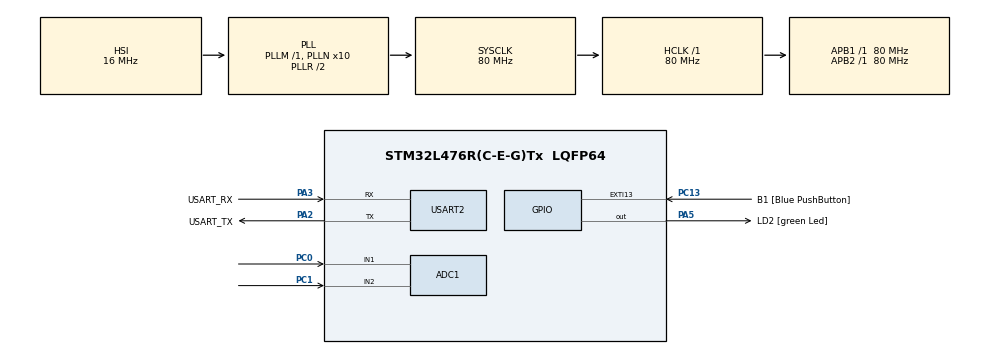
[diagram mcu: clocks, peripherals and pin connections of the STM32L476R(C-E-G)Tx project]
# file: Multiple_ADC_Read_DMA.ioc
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Mcu.Family=STM32L4
PA2.GPIO_PuPd=GPIO_NOPULL
RCC.CortexFreq_Value=80000000
ADC1.ContinuousConvMode=ENABLE
PH0-OSC_IN\ (PH0).Signal=RCC_OSC_IN
SH.ADCx_IN2.0=ADC1_IN2,IN2-Single-Ended
PA3.GPIO_PuPd=GPIO_NOPULL
PA2.GPIO_Speed=GPIO_SPEED_FREQ_VERY_HIGH
PC15-OSC32_OUT\ (PC15).Mode=LSE-External-Oscillator
PC13.GPIO_Label=B1 [Blue PushButton]
PA3.GPIO_Speed=GPIO_SPEED_FREQ_VERY_HIGH
RCC.SYSCLKSource=RCC_SYSCLKSOURCE_PLLCLK
ProjectManager.StackSize=0x400
PB3\ (JTDO-TRACESWO).Signal=SYS_JTDO-SWO
PC14-OSC32_IN\ (PC14).Mode=LSE-External-Oscillator
PA14\ (JTCK-SWCLK).Signal=SYS_JTCK-SWCLK
RCC.HCLKFreq_Value=80000000
RCC.APB2TimFreq_Value=80000000
Dma.ADC1.0.Direction=DMA_PERIPH_TO_MEMORY
Dma.ADC1.0.MemDataAlignment=DMA_MDATAALIGN_WORD
RCC.AHBFreq_Value=80000000
RCC.PREFETCH_ENABLE=1
ADC1.Channel-0\#ChannelRegularConversion=ADC_CHANNEL_1
RCC.HSE_VALUE=8000000
USART2.VirtualMode-Asynchronous=VM_ASYNC
Dma.ADC1.0.PeriphInc=DMA_PINC_DISABLE
PA5.GPIO_PuPd=GPIO_NOPULL
PC13.GPIO_PuPd=GPIO_NOPULL
ADC1.SamplingTime-0\#ChannelRegularConversion=ADC_SAMPLETIME_92CYCLES_5
Mcu.Package=LQFP64
PA2.GPIO_Label=USART_TX
ADC1.OffsetNumber-1\#ChannelRegularConversion=ADC_OFFSET_NONE
SH.ADCx_IN1.0=ADC1_IN1,IN1-Single-Ended
RCC.APB1TimFreq_Value=80000000
PA13\ (JTMS-SWDIO).Signal=SYS_JTMS-SWDIO
Dma.Request0=ADC1
PA3.Signal=USART2_RX
PA2.GPIO_Mode=GPIO_MODE_AF_PP
RCC.MSI_VALUE=4000000
RCC.PLLSourceVirtual=RCC_PLLSOURCE_HSI
PA14\ (JTCK-SWCLK).Mode=Serial_Wire
Dma.ADC1.0.Instance=DMA1_Channel1
ADC1.Rank-0\#ChannelRegularConversion=1
ADC1.OffsetNumber-0\#ChannelRegularConversion=ADC_OFFSET_NONE
PC13.Signal=GPXTI13
PC15-OSC32_OUT\ (PC15).Signal=RCC_OSC32_OUT
PA14\ (JTCK-SWCLK).GPIO_Label=TCK
PB3\ (JTDO-TRACESWO).GPIO_Label=SWO
PC0.Signal=ADCx_IN1
PH1-OSC_OUT\ (PH1).Signal=RCC_OSC_OUT
PA3.Mode=Asynchronous
Dma.ADC1.0.PeriphDataAlignment=DMA_PDATAALIGN_WORD
ProjectManager.TargetToolchain=MDK-ARM V5.27
Dma.ADC1.0.Mode=DMA_NORMAL
PA3.GPIO_Mode=GPIO_MODE_AF_PP
Dma.ADC1.0.Priority=DMA_PRIORITY_MEDIUM
ADC1.Channel-1\#ChannelRegularConversion=ADC_CHANNEL_2
RCC.USBFreq_Value=64000000
PA5.Signal=GPIO_Output
board=NUCLEO-L476RG
RCC.VCOOutputFreq_Value=160000000
RCC.APB2Freq_Value=80000000
PA5.GPIO_ModeDefaultOutputPP=GPIO_MODE_OUTPUT_PP
PA13\ (JTMS-SWDIO).GPIO_Label=TMS
RCC.ADCFreq_Value=64000000
ADC1.NbrOfConversion=2
Mcu.Name=STM32L476R(C-E-G)Tx
PA2.Signal=USART2_TX
PA13\ (JTMS-SWDIO).Mode=Serial_Wire
ADC1.SamplingTime-1\#ChannelRegularConversion=ADC_SAMPLETIME_92CYCLES_5
RCC.SYSCLKFreq_VALUE=80000000
ADC1.master=1
PA5.GPIO_Label=LD2 [green Led]
PC13.GPIO_ModeDefaultEXTI=GPIO_MODE_IT_FALLING
PC14-OSC32_IN\ (PC14).Signal=RCC_OSC32_IN
ADC1.Rank-1\#ChannelRegularConversion=2
Dma.ADC1.0.MemInc=DMA_MINC_ENABLE
ProjectManager.HeapSize=0x200
RCC.HSI_VALUE=16000000
PA5.GPIO_Speed=GPIO_SPEED_FREQ_LOW
NVIC.PriorityGroup=NVIC_PRIORITYGROUP_4
ADC1.NbrOfConversionFlag=1
RCC.PLLN=10
PA2.Mode=Asynchronous
NVIC.DMA1_Channel1_IRQn=true\:0\:0\:false\:false\:true\:false\:true
RCC.APB1Freq_Value=80000000
PC1.Signal=ADCx_IN2
PA3.GPIO_Label=USART_RX

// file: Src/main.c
/* USER CODE BEGIN Header */
/**
  ******************************************************************************
  * @file           : main.c
  * @brief          : Main program body
  ******************************************************************************
  * @attention
  *
  * <h2><center>&copy; Copyright (c) 2020 STMicroelectronics.
  * All rights reserved.</center></h2>
  *
  * This software component is licensed by ST under BSD 3-Clause license,
  * the "License"; You may not use this file except in compliance with the
  * License. You may obtain a copy of the License at:
  *                        opensource.org/licenses/BSD-3-Clause
  *
  ******************************************************************************
  */
/* USER CODE END Header */

#include "main.h"
#include "stdio.h"

/* USER CODE BEGIN PTD */
uint32_t data[2];
uint32_t ADCbuffer[2];
/* USER CODE END PTD */

ADC_HandleTypeDef hadc1;
DMA_HandleTypeDef hdma_adc1;

UART_HandleTypeDef huart2;

void SystemClock_Config(void);
static void MX_GPIO_Init(void);
static void MX_DMA_Init(void);
static void MX_ADC1_Init(void);
static void MX_USART2_UART_Init(void);

/* USER CODE BEGIN 0 */

void ConvCpltCallback(ADC_HandleTypeDef* hadc)
{
	if (hadc->Instance == ADC1)
	{
		data[0] = ADCbuffer[0];
		data[1] = ADCbuffer[1];

	}

}
/* USER CODE END 0 */

int main(void)
{

  /* MCU Configuration--------------------------------------------------------*/

  /* Reset of all peripherals, Initializes the Flash interface and the Systick. */
  HAL_Init();

  /* Configure the system clock */
  SystemClock_Config();

  /* Initialize all configured peripherals */
  MX_GPIO_Init();
  MX_DMA_Init();
  MX_ADC1_Init();
  MX_USART2_UART_Init();
  /* USER CODE BEGIN 2 */
  HAL_ADC_Start_DMA(&hadc1,ADCbuffer,2);
  /* USER CODE END 2 */

  /* Infinite loop */
  while (1)
  {
      printf("ADC1, CH0 Value is%c\n",data[0]);
      printf("ADC1, CH1 Value is%c\n",data[1]);

  }
}

void SystemClock_Config(void)
{
  RCC_OscInitTypeDef RCC_OscInitStruct = {0};
  RCC_ClkInitTypeDef RCC_ClkInitStruct = {0};
  RCC_PeriphCLKInitTypeDef PeriphClkInit = {0};

  /** Initializes the CPU, AHB and APB busses clocks
  */
  RCC_OscInitStruct.OscillatorType = RCC_OSCILLATORTYPE_HSI;
  RCC_OscInitStruct.HSIState = RCC_HSI_ON;
  RCC_OscInitStruct.HSICalibrationValue = RCC_HSICALIBRATION_DEFAULT;
  RCC_OscInitStruct.PLL.PLLState = RCC_PLL_ON;
  RCC_OscInitStruct.PLL.PLLSource = RCC_PLLSOURCE_HSI;
  RCC_OscInitStruct.PLL.PLLM = 1;
  RCC_OscInitStruct.PLL.PLLN = 10;
  RCC_OscInitStruct.PLL.PLLP = RCC_PLLP_DIV7;
  RCC_OscInitStruct.PLL.PLLQ = RCC_PLLQ_DIV2;
  RCC_OscInitStruct.PLL.PLLR = RCC_PLLR_DIV2;
  if (HAL_RCC_OscConfig(&RCC_OscInitStruct) != HAL_OK)
  {
    Error_Handler();
  }
  /** Initializes the CPU, AHB and APB busses clocks
  */
  RCC_ClkInitStruct.ClockType = RCC_CLOCKTYPE_HCLK|RCC_CLOCKTYPE_SYSCLK
                              |RCC_CLOCKTYPE_PCLK1|RCC_CLOCKTYPE_PCLK2;
  RCC_ClkInitStruct.SYSCLKSource = RCC_SYSCLKSOURCE_PLLCLK;
  RCC_ClkInitStruct.AHBCLKDivider = RCC_SYSCLK_DIV1;
  RCC_ClkInitStruct.APB1CLKDivider = RCC_HCLK_DIV1;
  RCC_ClkInitStruct.APB2CLKDivider = RCC_HCLK_DIV1;

  if (HAL_RCC_ClockConfig(&RCC_ClkInitStruct, FLASH_LATENCY_4) != HAL_OK)
  {
    Error_Handler();
  }
  PeriphClkInit.PeriphClockSelection = RCC_PERIPHCLK_USART2|RCC_PERIPHCLK_ADC;
  PeriphClkInit.Usart2ClockSelection = RCC_USART2CLKSOURCE_PCLK1;
  PeriphClkInit.AdcClockSelection = RCC_ADCCLKSOURCE_PLLSAI1;
  PeriphClkInit.PLLSAI1.PLLSAI1Source = RCC_PLLSOURCE_HSI;
  PeriphClkInit.PLLSAI1.PLLSAI1M = 1;
  PeriphClkInit.PLLSAI1.PLLSAI1N = 8;
  PeriphClkInit.PLLSAI1.PLLSAI1P = RCC_PLLP_DIV7;
  PeriphClkInit.PLLSAI1.PLLSAI1Q = RCC_PLLQ_DIV2;
  PeriphClkInit.PLLSAI1.PLLSAI1R = RCC_PLLR_DIV2;
  PeriphClkInit.PLLSAI1.PLLSAI1ClockOut = RCC_PLLSAI1_ADC1CLK;
  if (HAL_RCCEx_PeriphCLKConfig(&PeriphClkInit) != HAL_OK)
  {
    Error_Handler();
  }
  /** Configure the main internal regulator output voltage
  */
  if (HAL_PWREx_ControlVoltageScaling(PWR_REGULATOR_VOLTAGE_SCALE1) != HAL_OK)
  {
    Error_Handler();
  }
}

static void MX_ADC1_Init(void)
{

  ADC_MultiModeTypeDef multimode = {0};
  ADC_ChannelConfTypeDef sConfig = {0};

  /** Common config
  */
  hadc1.Instance = ADC1;
  hadc1.Init.ClockPrescaler = ADC_CLOCK_ASYNC_DIV1;
  hadc1.Init.Resolution = ADC_RESOLUTION_12B;
  hadc1.Init.DataAlign = ADC_DATAALIGN_RIGHT;
  hadc1.Init.ScanConvMode = ADC_SCAN_ENABLE;
  hadc1.Init.EOCSelection = ADC_EOC_SINGLE_CONV;
  hadc1.Init.LowPowerAutoWait = DISABLE;
  hadc1.Init.ContinuousConvMode = ENABLE;
  hadc1.Init.NbrOfConversion = 2;
  hadc1.Init.DiscontinuousConvMode = DISABLE;
  hadc1.Init.NbrOfDiscConversion = 1;
  hadc1.Init.ExternalTrigConv = ADC_SOFTWARE_START;
  hadc1.Init.ExternalTrigConvEdge = ADC_EXTERNALTRIGCONVEDGE_NONE;
  hadc1.Init.DMAContinuousRequests = DISABLE;
  hadc1.Init.Overrun = ADC_OVR_DATA_PRESERVED;
  hadc1.Init.OversamplingMode = DISABLE;
  if (HAL_ADC_Init(&hadc1) != HAL_OK)
  {
    Error_Handler();
  }
  /** Configure the ADC multi-mode
  */
  multimode.Mode = ADC_MODE_INDEPENDENT;
  if (HAL_ADCEx_MultiModeConfigChannel(&hadc1, &multimode) != HAL_OK)
  {
    Error_Handler();
  }
  /** Configure Regular Channel
  */
  sConfig.Channel = ADC_CHANNEL_1;
  sConfig.Rank = ADC_REGULAR_RANK_1;
  sConfig.SamplingTime = ADC_SAMPLETIME_92CYCLES_5;
  sConfig.SingleDiff = ADC_SINGLE_ENDED;
  sConfig.OffsetNumber = ADC_OFFSET_NONE;
  sConfig.Offset = 0;
  if (HAL_ADC_ConfigChannel(&hadc1, &sConfig) != HAL_OK)
  {
    Error_Handler();
  }
  /** Configure Regular Channel
  */
  sConfig.Channel = ADC_CHANNEL_2;
  sConfig.Rank = ADC_REGULAR_RANK_2;
  if (HAL_ADC_ConfigChannel(&hadc1, &sConfig) != HAL_OK)
  {
    Error_Handler();
  }

}

static void MX_USART2_UART_Init(void)
{

  huart2.Instance = USART2;
  huart2.Init.BaudRate = 115200;
  huart2.Init.WordLength = UART_WORDLENGTH_8B;
  huart2.Init.StopBits = UART_STOPBITS_1;
  huart2.Init.Parity = UART_PARITY_NONE;
  huart2.Init.Mode = UART_MODE_TX_RX;
  huart2.Init.HwFlowCtl = UART_HWCONTROL_NONE;
  huart2.Init.OverSampling = UART_OVERSAMPLING_16;
  huart2.Init.OneBitSampling = UART_ONE_BIT_SAMPLE_DISABLE;
  huart2.AdvancedInit.AdvFeatureInit = UART_ADVFEATURE_NO_INIT;
  if (HAL_UART_Init(&huart2) != HAL_OK)
  {
    Error_Handler();
  }

}

static void MX_DMA_Init(void)
{

  /* DMA controller clock enable */
  __HAL_RCC_DMA1_CLK_ENABLE();

  /* DMA interrupt init */
  /* DMA1_Channel1_IRQn interrupt configuration */
  HAL_NVIC_SetPriority(DMA1_Channel1_IRQn, 0, 0);
  HAL_NVIC_EnableIRQ(DMA1_Channel1_IRQn);

}

static void MX_GPIO_Init(void)
{
  GPIO_InitTypeDef GPIO_InitStruct = {0};

  /* GPIO Ports Clock Enable */
  __HAL_RCC_GPIOC_CLK_ENABLE();
  __HAL_RCC_GPIOH_CLK_ENABLE();
  __HAL_RCC_GPIOA_CLK_ENABLE();
  __HAL_RCC_GPIOB_CLK_ENABLE();

  /*Configure GPIO pin Output Level */
  HAL_GPIO_WritePin(LD2_GPIO_Port, LD2_Pin, GPIO_PIN_RESET);

  /*Configure GPIO pin : B1_Pin */
  GPIO_InitStruct.Pin = B1_Pin;
  GPIO_InitStruct.Mode = GPIO_MODE_IT_FALLING;
  GPIO_InitStruct.Pull = GPIO_NOPULL;
  HAL_GPIO_Init(B1_GPIO_Port, &GPIO_InitStruct);

  /*Configure GPIO pin : LD2_Pin */
  GPIO_InitStruct.Pin = LD2_Pin;
  GPIO_InitStruct.Mode = GPIO_MODE_OUTPUT_PP;
  GPIO_InitStruct.Pull = GPIO_NOPULL;
  GPIO_InitStruct.Speed = GPIO_SPEED_FREQ_LOW;
  HAL_GPIO_Init(LD2_GPIO_Port, &GPIO_InitStruct);

}

void Error_Handler(void)
{
}

/************************ (C) COPYRIGHT STMicroelectronics *****END OF FILE****/
